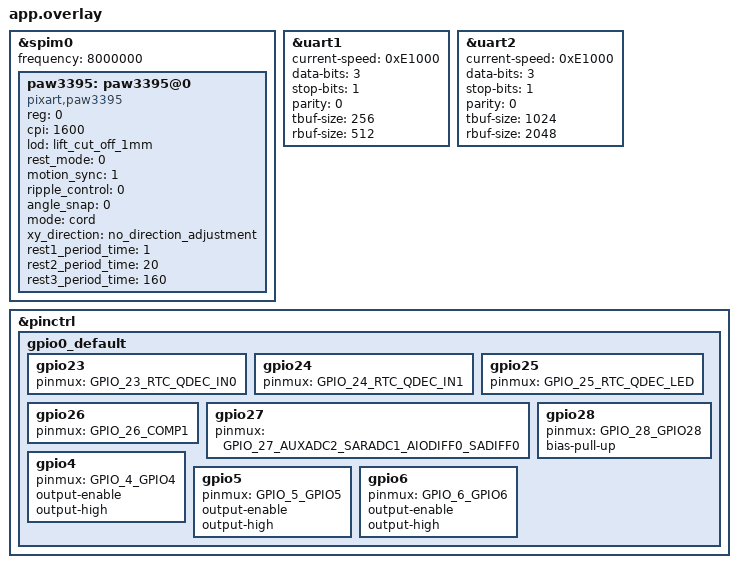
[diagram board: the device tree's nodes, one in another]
/* Copyright Statement:
 *
 * (C) 2025  Airoha Technology Corp. All rights reserved.
 *
 * This software/firmware and related documentation ("Airoha Software") are
 * protected under relevant copyright laws. The information contained herein
 * is confidential and proprietary to Airoha Technology Corp. ("Airoha") and/or its licensors.
 * Without the prior written permission of Airoha and/or its licensors,
 * any reproduction, modification, use or disclosure of Airoha Software,
 * and information contained herein, in whole or in part, shall be strictly prohibited.
 * You may only use, reproduce, modify, or distribute (as applicable) Airoha Software
 * if you have agreed to and been bound by the applicable license agreement with
 * Airoha ("License Agreement") and been granted explicit permission to do so within
 * the License Agreement ("Permitted User").  If you are not a Permitted User,
 * please cease any access or use of Airoha Software immediately.
 * BY OPENING THIS FILE, RECEIVER HEREBY UNEQUIVOCALLY ACKNOWLEDGES AND AGREES
 * THAT THE SOFTWARE/FIRMWARE AND ITS DOCUMENTATIONS ("AIROHA SOFTWARE")
 * RECEIVED FROM AIROHA AND/OR ITS REPRESENTATIVES ARE PROVIDED
 * TO RECEIVER ON AN "AS-IS" BASIS ONLY. AIROHA EXPRESSLY DISCLAIMS ANY AND ALL
 * WARRANTIES, EXPRESS OR IMPLIED, INCLUDING BUT NOT LIMITED TO THE IMPLIED WARRANTIES OF
 * MERCHANTABILITY, FITNESS FOR A PARTICULAR PURPOSE OR NONINFRINGEMENT.
 * NEITHER DOES AIROHA PROVIDE ANY WARRANTY WHATSOEVER WITH RESPECT TO THE
 * SOFTWARE OF ANY THIRD PARTY WHICH MAY BE USED BY, INCORPORATED IN, OR
 * SUPPLIED WITH AIROHA SOFTWARE, AND RECEIVER AGREES TO LOOK ONLY TO SUCH
 * THIRD PARTY FOR ANY WARRANTY CLAIM RELATING THERETO. RECEIVER EXPRESSLY ACKNOWLEDGES
 * THAT IT IS RECEIVER'S SOLE RESPONSIBILITY TO OBTAIN FROM ANY THIRD PARTY ALL PROPER LICENSES
 * CONTAINED IN AIROHA SOFTWARE. AIROHA SHALL ALSO NOT BE RESPONSIBLE FOR ANY AIROHA
 * SOFTWARE RELEASES MADE TO RECEIVER'S SPECIFICATION OR TO CONFORM TO A PARTICULAR
 * STANDARD OR OPEN FORUM. RECEIVER'S SOLE AND EXCLUSIVE REMEDY AND AIROHA'S ENTIRE AND
 * CUMULATIVE LIABILITY WITH RESPECT TO AIROHA SOFTWARE RELEASED HEREUNDER WILL BE,
 * AT AIROHA'S OPTION, TO REVISE OR REPLACE AIROHA SOFTWARE AT ISSUE,
 * OR REFUND ANY SOFTWARE LICENSE FEES OR SERVICE CHARGE PAID BY RECEIVER TO
 * AIROHA FOR SUCH AIROHA SOFTWARE AT ISSUE.
 */

&spim0 {
    frequency = <8000000>;
    status = "okay";
	paw3395: paw3395@0{
		compatible = "pixart,paw3395";
		reg= <0>;
		cpi = <1600>;
		lod = "lift_cut_off_1mm";
		rest_mode = <0>;
		motion_sync = <1>;
		ripple_control = <0>;
		angle_snap = <0>;
		mode = "cord";
		xy_direction = "no_direction_adjustment";
		rest1_period_time = <1>;
		rest2_period_time = <20>;
		rest3_period_time = <160>;
		status = "okay";
    };
};

&uart1 {
    status = "okay";
    current-speed = < 0xE1000 >;
    data-bits = <3>;
    stop-bits = <1>;
    parity = <0>;
    tbuf-size = <256>;
    rbuf-size = <512>;
};
&uart2 {
    status = "okay";
    current-speed = < 0xE1000 >;
    data-bits = <3>;
    stop-bits = <1>;
    parity = <0>;
    tbuf-size = <1024>;
    rbuf-size = <2048>;
};

&pinctrl {
    gpio0_default: gpio0_default {
        gpio23{
            pinmux = <GPIO_23_RTC_QDEC_IN0>;
        };
        gpio24{
            pinmux = <GPIO_24_RTC_QDEC_IN1>;
        };
        gpio25{
            pinmux = <GPIO_25_RTC_QDEC_LED>;
        };
        gpio26{
            pinmux = <GPIO_26_COMP1>;
        };
        gpio27{
            pinmux = <GPIO_27_AUXADC2_SARADC1_AIODIFF0_SADIFF0>;
        };
        gpio28{
            pinmux = <GPIO_28_GPIO28>;
            bias-pull-up;
        };
        gpio4{
            pinmux = <GPIO_4_GPIO4>;
            output-enable;
            output-high;
        };
        gpio5{
            pinmux = <GPIO_5_GPIO5>;
            output-enable;
            output-high;
        };
        gpio6{
            pinmux = <GPIO_6_GPIO6>;
            output-enable;
            output-high;
        };
    };
};

